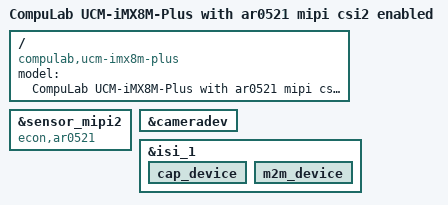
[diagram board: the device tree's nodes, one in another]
// SPDX-License-Identifier: (GPL-2.0+ OR MIT)
/*
 * Copyright 2021 CompuLab
 */

/dts-v1/;

#include "som-imx8m-plus.dts"
#include "som-imx8m-plus_mipi-csi2.dtsi"

/ {
	model = "CompuLab UCM-iMX8M-Plus with ar0521 mipi csi2 enabled";
	compatible = "compulab,ucm-imx8m-plus", "fsl,imx8mp";
};

&sensor_mipi2 {
	compatible = "econ,ar0521", "ar0521";
};

&cameradev {
	status = "okay";
};

&isi_1 {
	status = "okay";

	cap_device {
		status = "okay";
	};

	m2m_device {
		status = "okay";
	};
};
